AUTOSAR XML (schema 4-2-2)
package /Components
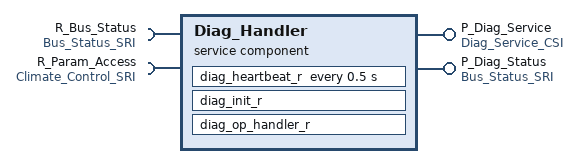
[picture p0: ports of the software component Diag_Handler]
  service sw component type Diag_Handler
    provide port P_Diag_Service: provided-interface=Diag_Service_CSI
    provide port P_Diag_Status: provided-interface=Bus_Status_SRI
    require port R_Bus_Status: required-interface=Bus_Status_SRI
    require port R_Param_Access: required-interface=Climate_Control_SRI
    behavior Diag_Handler_InternalBehavior
      init event Diag_Init: start-on-event=diag_init_r
      operation invoked event Diag_Operation_Invoked: start-on-event=diag_op_handler_r
      timing event Diag_Heartbeat: start-on-event=diag_heartbeat_r, period=0.5
      runnable diag_init_r: symbol=Diag_Init
        data-read-access:
          access init_read_bus_online: accessed-variable=R_Bus_Status.bus_online
        data-receive-point-by-arguments:
          access init_rx_param_temp: accessed-variable=R_Param_Access.hvac_target_temp
        data-send-points:
          access init_tx_status_online: accessed-variable=P_Diag_Status.bus_online
        data-write-access:
          access init_write_status_load: accessed-variable=P_Diag_Status.bus_load
      runnable diag_op_handler_r: symbol=Diag_Operation_Handler
        data-read-access:
          access op_read_bus_error_count: accessed-variable=R_Bus_Status.bus_error_count
        data-receive-point-by-arguments:
          access op_rx_service_args: accessed-variable=P_Diag_Service.seat_position_cmd
        data-send-points:
          access op_tx_status_error_count: accessed-variable=P_Diag_Status.bus_error_count
        data-write-access:
          access op_write_status_online: accessed-variable=P_Diag_Status.bus_online
      runnable diag_heartbeat_r: symbol=Diag_Heartbeat
        data-read-access:
          access hb_read_bus_online: accessed-variable=R_Bus_Status.bus_online
        data-receive-point-by-arguments:
          access hb_rx_param_temp: accessed-variable=R_Param_Access.hvac_target_temp
        data-send-points:
          access hb_tx_status_online: accessed-variable=P_Diag_Status.bus_online
        data-write-access:
          access hb_write_status_load: accessed-variable=P_Diag_Status.bus_load
